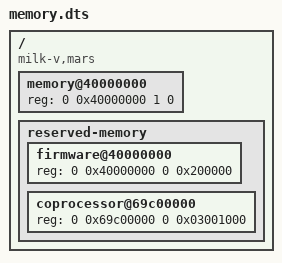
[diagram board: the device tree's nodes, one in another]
/dts-v1/;
/memreserve/ 0x41000000 0x1000;
/ {
    compatible = "milk-v,mars", "starfive,jh7110";
    #address-cells = <2>;
    #size-cells = <2>;
    memory@40000000 {
        device_type = "memory";
        reg = <0 0x40000000 1 0>;
    };
    reserved-memory {
        #address-cells = <2>;
        #size-cells = <2>;
        ranges;
        firmware@40000000 { reg = <0 0x40000000 0 0x200000>; };
        coprocessor@69c00000 { reg = <0 0x69c00000 0 0x03001000>; };
    };
};
